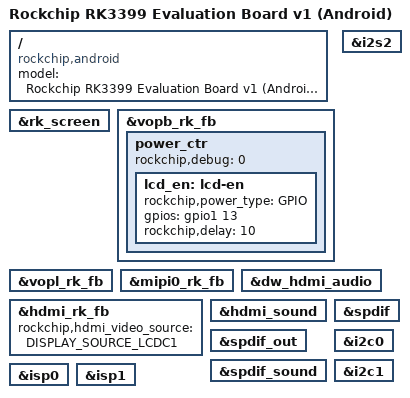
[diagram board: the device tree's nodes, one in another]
/*
 * Copyright (c) 2016 Fuzhou Rockchip Electronics Co., Ltd
 *
 * This file is dual-licensed: you can use it either under the terms
 * of the GPL or the X11 license, at your option. Note that this dual
 * licensing only applies to this file, and not this project as a
 * whole.
 *
 *  a) This file is free software; you can redistribute it and/or
 *     modify it under the terms of the GNU General Public License as
 *     published by the Free Software Foundation; either version 2 of the
 *     License, or (at your option) any later version.
 *
 *     This file is distributed in the hope that it will be useful,
 *     but WITHOUT ANY WARRANTY; without even the implied warranty of
 *     MERCHANTABILITY or FITNESS FOR A PARTICULAR PURPOSE.  See the
 *     GNU General Public License for more details.
 *
 * Or, alternatively,
 *
 *  b) Permission is hereby granted, free of charge, to any person
 *     obtaining a copy of this software and associated documentation
 *     files (the "Software"), to deal in the Software without
 *     restriction, including without limitation the rights to use,
 *     copy, modify, merge, publish, distribute, sublicense, and/or
 *     sell copies of the Software, and to permit persons to whom the
 *     Software is furnished to do so, subject to the following
 *     conditions:
 *
 *     The above copyright notice and this permission notice shall be
 *     included in all copies or substantial portions of the Software.
 *
 *     THE SOFTWARE IS PROVIDED "AS IS", WITHOUT WARRANTY OF ANY KIND,
 *     EXPRESS OR IMPLIED, INCLUDING BUT NOT LIMITED TO THE WARRANTIES
 *     OF MERCHANTABILITY, FITNESS FOR A PARTICULAR PURPOSE AND
 *     NONINFRINGEMENT. IN NO EVENT SHALL THE AUTHORS OR COPYRIGHT
 *     HOLDERS BE LIABLE FOR ANY CLAIM, DAMAGES OR OTHER LIABILITY,
 *     WHETHER IN AN ACTION OF CONTRACT, TORT OR OTHERWISE, ARISING
 *     FROM, OUT OF OR IN CONNECTION WITH THE SOFTWARE OR THE USE OR
 *     OTHER DEALINGS IN THE SOFTWARE.
 */

/dts-v1/;

#include "rk3399-evb-rev1.dtsi"
#include "rk3399-android-6.0.dtsi"

/ {
	model = "Rockchip RK3399 Evaluation Board v1 (Android)";
	compatible = "rockchip,android", "rockchip,rk3399-evb-rev1", "rockchip,rk3399";
};

&rk_screen {
	#include <dt-bindings/display/screen-timing/lcd-tv080wum-nl0-mipi.dtsi>
};

&vopb_rk_fb {
	status = "okay";
	power_ctr: power_ctr {
		rockchip,debug = <0>;
		lcd_en: lcd-en {
			rockchip,power_type = <GPIO>;
			gpios = <&gpio1 13 GPIO_ACTIVE_HIGH>;
			rockchip,delay = <10>;
		};

		/*lcd_cs: lcd-cs {
			rockchip,power_type = <GPIO>;
			gpios = <&gpio0 21 GPIO_ACTIVE_HIGH>;//GPIO_C5 = 21
			rockchip,delay = <10>;
		};*/

		/*lcd_rst: lcd-rst {
			rockchip,power_type = <GPIO>;
			gpios = <&gpio3 GPIO_D6 GPIO_ACTIVE_HIGH>;
			rockchip,delay = <5>;
		};*/
	};
};

&vopl_rk_fb {
	status = "okay";
};

&mipi0_rk_fb {
	status = "okay";
};

&hdmi_rk_fb {
	status = "okay";
	rockchip,hdmi_video_source = <DISPLAY_SOURCE_LCDC1>;
};

&i2s2 {
	status = "okay";
};

&dw_hdmi_audio {
	status = "okay";
};

&hdmi_sound {
	status = "okay";
};

&spdif {
	status = "okay";
};

&spdif_out {
	status = "okay";
};

&spdif_sound {
	status = "okay";
};

&i2c0 {
	status = "okay";
};

&i2c1 {
	status = "okay";
};

&isp0 {
	status = "okay";
};

&isp1 {
	status = "okay";
};
